# MPU_WD_TIMER register map
Vendor: Texas Instruments
Peripheral module from a debugger description file (folder am571x).
Registers are 32-bit, read-write, reset 0x0 unless marked. A register's access mark holds for its fields unless they carry their own. Offsets are as the file gives them; lines under a group give offsets from that group; [hi:lo] are bit positions; {n}, {i} and the like mark numbered series; 'fields as' and 'values as' point back to an identical list; <NAME> marks a mode.

## MPU_WD_TIMER
0x00 WDT_LOAD_REGISTER_0 — When a new value is stored in this register, the is immediately loaded with this value and the prescaler state is cleared. This register is reset by warm reset of the MPU core.
  [31:0] NEWCOUNT — New value to load intoWDT_COUNT_REGISTER_0.
0x04 WDT_COUNT_REGISTER_0 ro — This register is a 32-bit decrementing counter. The decrement rate is programmed in the. The can be read to get the current count. It decrements if the MPU_WD_TIMER_C0 is enabled ([0] ENABLE = 0x1). If the MPU core is in debug state, the counter does not decrement until the MPU core returns to non-debug state. The decrements down to zero and stops. The only way to update the is to write to the . If a software failure prevents the from being refreshed, the reaches zero, the watchdog timeout status flag is set and all interrupt requests or reset requests enabled in the are signalled. If a reset request is enabled, the global PRCM is then responsible for resetting the MPUSS. Debug state is inferred by monitoring the DBGACK signal of the MPU core. This register is reset by warm reset of the MPU core.
  [31:0] CURRENTCOUNT — Current count of the MPU_WD_TIMER.
0x08 WDT_WARNING_REGISTER_0 — The is compared to the . If is less than or equal to the and [8] WARNEN = 0b1, a warning interrupt is signalled to the MPU_INTC. The warning condition can be used to signal an interrupt that gives software a notice that the MPU_WD_TIMER_C0 is getting close to a timeout, when a more serious action should be taken.
  [31:0] WARNING_WATERMARK — A warning condition occurs when theWDT_COUNT_REGISTER_0 value is less than or equal to the WDT_WARNING_REGISTER_0.
0x0C WDT_PRESCALER_REGISTER_0 access per field — This register is used to set the count rate of the MPU_WD_TIMER_C0 counter.
  [9:0] PRESCALER rw — Sets the prescaler ratio.WDT_COUNT_REGISTER_0 decrements every (PRESCALER + 1) MPU_DPLL_CLK clocks. Note: If the prescaler is set to (MPU_DPLL_CLK [in MHz] - 1), the MPU_WD_TIMER_C0 counter counts at a 1 microsecond rate.
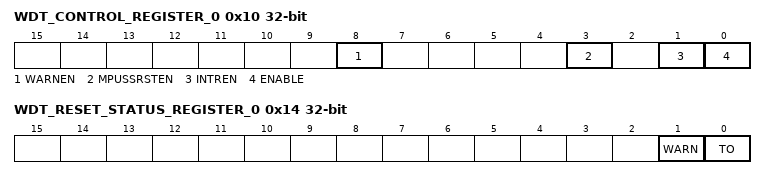
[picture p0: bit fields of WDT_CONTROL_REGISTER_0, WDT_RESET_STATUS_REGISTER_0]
0x10 WDT_CONTROL_REGISTER_0 access per field — This register controls the behavior of the MPU_WD_TIMER_C0. This register is reset by warm reset of the MPU core.
  [8] WARNEN rw — Warning Interrupt Enable. If this bit is set and the warning watermark test is true, a warning interrupt is generated to the MPU_INTC.
  [3] MPUSSRSTEN rw — MPUSS Reset Enable. If this field is 0b1 when the timer reaches zero, a request is sent to the global PRCM for a global warm reset.
  [1] INTREN rw — Interrupt Enable. If this field is 0b1 when the timer reaches zero, an interrupt request is sent to the MPU_INTC.
  [0] ENABLE rw — Enable for MPU_WD_TIMER_C0. 0: MPU_WD_TIMER_C0 is disabled. It will not count down and it will not generate a reset request. All MPU_WD_TIMER_C0 registers may be accessed. 1: MPU_WD_TIMER_C0 is enabled. It will count down and generate a reset request if it reaches 0. This bit is reset by warm or power-on reset.
0x14 WDT_RESET_STATUS_REGISTER_0 access not given — The TO bit indicated that this MPU_WD_TIMER_C0 has timed out. This register is not reset by warm reset, but only by cold reset.
  [1] WARN — Warning. Indicates that the count has passed the warning watermark level while theWDT_CONTROL_REGISTER_0[8] WARNEN bit was set. Write a '1' to this bit to reset it. (access RW W1toClr)
  [0] TO — Timeout. Indicates theWDT_COUNT_REGISTER_0 has reached zero (timed out) and the signalling enabled in the WDT_CONTROL_REGISTER_0 has occurred. Can be used to determine which MPU_WD_TIMER_C0 instance caused a reset. Write a '1' to this bit to reset it. (access RW W1toClr)
